# PIC32MK0512GPL064 register map
Vendor: Microchip
Registers are 32-bit, read-write, no defined reset value unless marked. A register's access mark holds for its fields unless they carry their own. Addresses are absolute, and some are shared; only a register's first bit layout is shown; [hi:lo] are bit positions.

## ICAP7
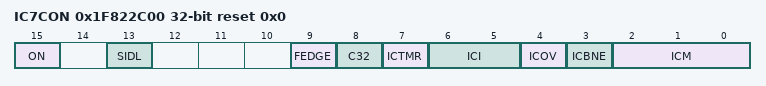
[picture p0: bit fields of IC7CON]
0x1F822C00 IC7CON reset 0x0
  [15] ON, [13] SIDL, [9] FEDGE, [8] C32, [7] ICTMR, [6:5] ICI, [4] ICOV ro, [3] ICBNE ro, [2:0] ICM
0x1F822C10 IC7BUF ro — (power-on value xxxxxxxxxxxxxxxxxxxxxxxxxxxxxxxx)

## ICAP8
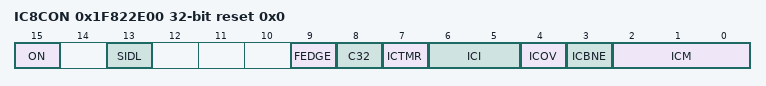
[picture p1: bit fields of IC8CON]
0x1F822E00 IC8CON reset 0x0
  [15] ON, [13] SIDL, [9] FEDGE, [8] C32, [7] ICTMR, [6:5] ICI, [4] ICOV ro, [3] ICBNE ro, [2:0] ICM
0x1F822E10 IC8BUF ro — (power-on value xxxxxxxxxxxxxxxxxxxxxxxxxxxxxxxx)

## ICAP9
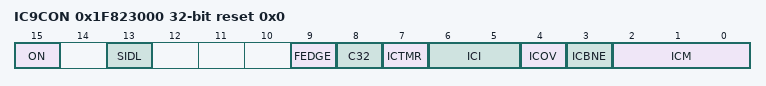
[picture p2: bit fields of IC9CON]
0x1F823000 IC9CON reset 0x0
  [15] ON, [13] SIDL, [9] FEDGE, [8] C32, [7] ICTMR, [6:5] ICI, [4] ICOV ro, [3] ICBNE ro, [2:0] ICM
0x1F823010 IC9BUF ro — (power-on value xxxxxxxxxxxxxxxxxxxxxxxxxxxxxxxx)

## OCMP1
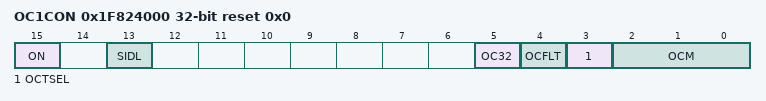
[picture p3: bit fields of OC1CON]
0x1F824000 OC1CON reset 0x0
  [15] ON, [13] SIDL, [5] OC32, [4] OCFLT ro, [3] OCTSEL, [2:0] OCM
0x1F824010 OC1R — (power-on value xxxxxxxxxxxxxxxxxxxxxxxxxxxxxxxx)
0x1F824020 OC1RS — (power-on value xxxxxxxxxxxxxxxxxxxxxxxxxxxxxxxx)

## OCMP2
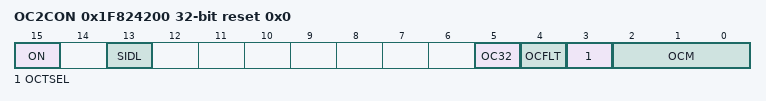
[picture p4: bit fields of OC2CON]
0x1F824200 OC2CON reset 0x0
  [15] ON, [13] SIDL, [5] OC32, [4] OCFLT ro, [3] OCTSEL, [2:0] OCM
0x1F824210 OC2R — (power-on value xxxxxxxxxxxxxxxxxxxxxxxxxxxxxxxx)
0x1F824220 OC2RS — (power-on value xxxxxxxxxxxxxxxxxxxxxxxxxxxxxxxx)

## OCMP3
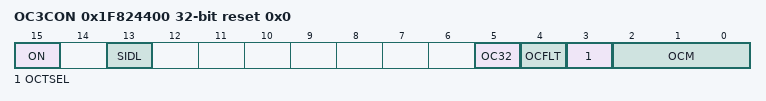
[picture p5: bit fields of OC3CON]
0x1F824400 OC3CON reset 0x0
  [15] ON, [13] SIDL, [5] OC32, [4] OCFLT ro, [3] OCTSEL, [2:0] OCM
0x1F824410 OC3R — (power-on value xxxxxxxxxxxxxxxxxxxxxxxxxxxxxxxx)
0x1F824420 OC3RS — (power-on value xxxxxxxxxxxxxxxxxxxxxxxxxxxxxxxx)

## OCMP4
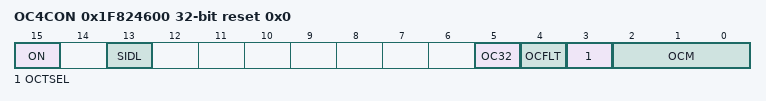
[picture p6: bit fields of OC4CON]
0x1F824600 OC4CON reset 0x0
  [15] ON, [13] SIDL, [5] OC32, [4] OCFLT ro, [3] OCTSEL, [2:0] OCM
0x1F824610 OC4R — (power-on value xxxxxxxxxxxxxxxxxxxxxxxxxxxxxxxx)
0x1F824620 OC4RS — (power-on value xxxxxxxxxxxxxxxxxxxxxxxxxxxxxxxx)

## OCMP5
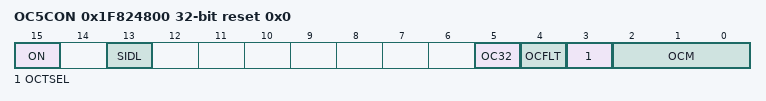
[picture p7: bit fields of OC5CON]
0x1F824800 OC5CON reset 0x0
  [15] ON, [13] SIDL, [5] OC32, [4] OCFLT ro, [3] OCTSEL, [2:0] OCM
0x1F824810 OC5R — (power-on value xxxxxxxxxxxxxxxxxxxxxxxxxxxxxxxx)
0x1F824820 OC5RS — (power-on value xxxxxxxxxxxxxxxxxxxxxxxxxxxxxxxx)

## OCMP6
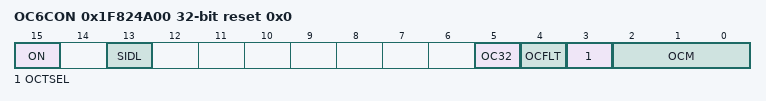
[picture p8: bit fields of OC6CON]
0x1F824A00 OC6CON reset 0x0
  [15] ON, [13] SIDL, [5] OC32, [4] OCFLT ro, [3] OCTSEL, [2:0] OCM
0x1F824A10 OC6R — (power-on value xxxxxxxxxxxxxxxxxxxxxxxxxxxxxxxx)
0x1F824A20 OC6RS — (power-on value xxxxxxxxxxxxxxxxxxxxxxxxxxxxxxxx)

## OCMP7
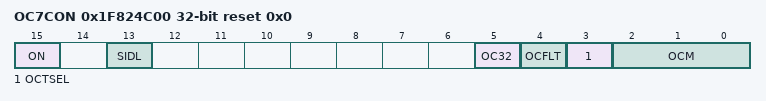
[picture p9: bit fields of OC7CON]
0x1F824C00 OC7CON reset 0x0
  [15] ON, [13] SIDL, [5] OC32, [4] OCFLT ro, [3] OCTSEL, [2:0] OCM
0x1F824C10 OC7R — (power-on value xxxxxxxxxxxxxxxxxxxxxxxxxxxxxxxx)
0x1F824C20 OC7RS — (power-on value xxxxxxxxxxxxxxxxxxxxxxxxxxxxxxxx)

## OCMP8
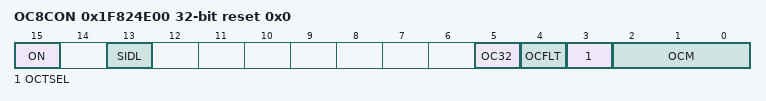
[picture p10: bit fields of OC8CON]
0x1F824E00 OC8CON reset 0x0
  [15] ON, [13] SIDL, [5] OC32, [4] OCFLT ro, [3] OCTSEL, [2:0] OCM
0x1F824E10 OC8R — (power-on value xxxxxxxxxxxxxxxxxxxxxxxxxxxxxxxx)
0x1F824E20 OC8RS — (power-on value xxxxxxxxxxxxxxxxxxxxxxxxxxxxxxxx)

## OCMP9
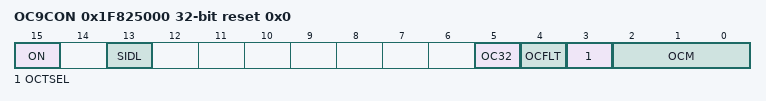
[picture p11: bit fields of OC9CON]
0x1F825000 OC9CON reset 0x0
  [15] ON, [13] SIDL, [5] OC32, [4] OCFLT ro, [3] OCTSEL, [2:0] OCM
0x1F825010 OC9R — (power-on value xxxxxxxxxxxxxxxxxxxxxxxxxxxxxxxx)
0x1F825020 OC9RS — (power-on value xxxxxxxxxxxxxxxxxxxxxxxxxxxxxxxx)

## I2C1
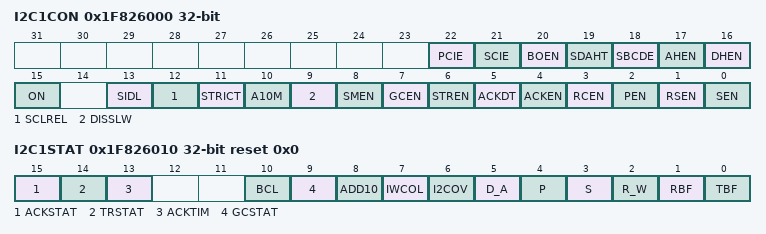
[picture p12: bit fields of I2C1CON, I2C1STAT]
0x1F826000 I2C1CON — (power-on value ---------00000000x01000000000000)
  [22] PCIE, [21] SCIE, [20] BOEN, [19] SDAHT, [18] SBCDE, [17] AHEN, [16] DHEN, [15] ON, [13] SIDL, [12] SCLREL, [11] STRICT, [10] A10M, [9] DISSLW, [8] SMEN, [7] GCEN, [6] STREN, [5] ACKDT, [4] ACKEN, [3] RCEN, [2] PEN, [1] RSEN, [0] SEN
0x1F826010 I2C1STAT reset 0x0
  [15] ACKSTAT ro
  [14] TRSTAT ro
  [13] ACKTIM ro
  [10] BCL — (can only be cleared)
  [9] GCSTAT ro
  [8] ADD10 ro
  [7] IWCOL — (can only be cleared)
  [6] I2COV — (can only be cleared)
  [5] D_A ro
  [4] P — (can only be cleared)
  [3] S — (can only be cleared)
  [2] R_W ro
  [1] RBF ro
  [0] TBF ro
0x1F826020 I2C1ADD reset 0x0
  [9:0] I2CADD
0x1F826030 I2C1MSK reset 0x0
  [9:0] I2CMSK
0x1F826040 I2C1BRG reset 0x0
  [15:0] I2CBRG
0x1F826050 I2C1TRN wo reset 0xFF
  [7:0] I2CTRN
0x1F826060 I2C1RCV ro reset 0x0
  [7:0] I2CRCV
